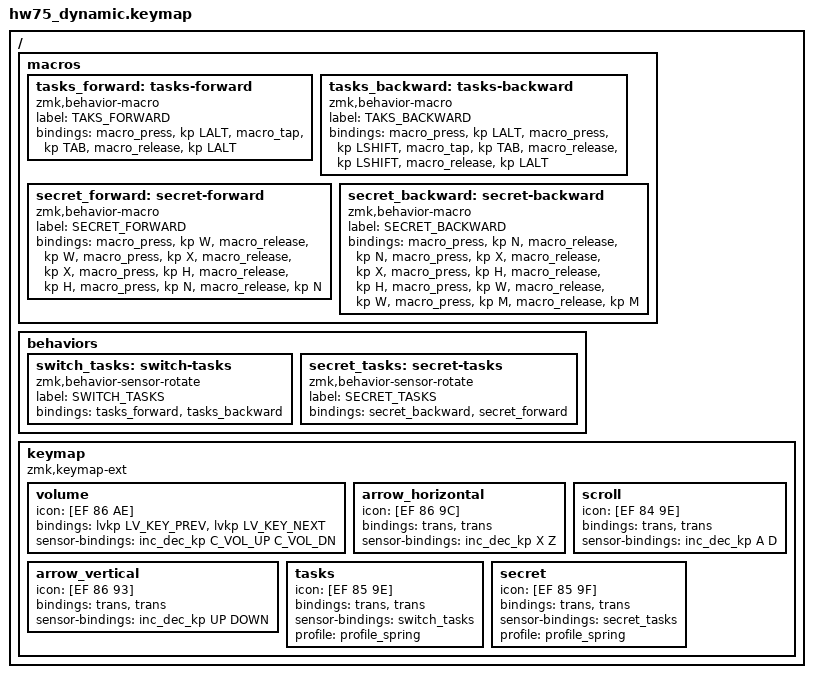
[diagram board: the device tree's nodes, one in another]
/*
 * Copyright (c) 2022 The ZMK Contributors
 * SPDX-License-Identifier: MIT
 */

#include <behaviors.dtsi>
#include <behaviors/lvgl_key_press.dtsi>
#include <behaviors/sensor_rotate_mouse_wheel.dtsi>
#include <dt-bindings/zmk/keys.h>
#include <dt-bindings/zmk/rgb.h>
#include <dt-bindings/zmk/lvgl.h>
#include <dt-bindings/zmk/mouse.h>

/ {
	macros {
		tasks_forward: tasks-forward {
			label = "TAKS_FORWARD";
			compatible = "zmk,behavior-macro";
			#binding-cells = <0>;
			bindings = <&macro_press   &kp LALT>,
				   <&macro_tap     &kp TAB>,
				   <&macro_release &kp LALT>;
		};

		tasks_backward: tasks-backward {
			label = "TAKS_BACKWARD";
			compatible = "zmk,behavior-macro";
			#binding-cells = <0>;
			bindings = <&macro_press   &kp LALT>,
				   <&macro_press   &kp LSHIFT>,
				   <&macro_tap     &kp TAB>,
				   <&macro_release &kp LSHIFT>,
				   <&macro_release &kp LALT>;
		};

		secret_forward: secret-forward {
			label = "SECRET_FORWARD";
			compatible = "zmk,behavior-macro";
			#binding-cells = <0>;
			bindings = <&macro_press   &kp W>,
				   <&macro_release   &kp W>,
				   <&macro_press   &kp X>,
				   <&macro_release   &kp X>,
				   <&macro_press     &kp H>,
				   <&macro_release   &kp H>,
				   <&macro_press &kp N>,
				   <&macro_release &kp N>;
		};

		secret_backward: secret-backward {
			label = "SECRET_BACKWARD";
			compatible = "zmk,behavior-macro";
			#binding-cells = <0>;
			bindings = <&macro_press   &kp N>,
				   <&macro_release   &kp N>,
				   <&macro_press   &kp X>,
				   <&macro_release   &kp X>,
				   <&macro_press     &kp H>,
				   <&macro_release   &kp H>,
				   <&macro_press &kp W>,
				   <&macro_release &kp W>,
				   <&macro_press &kp M>,
				   <&macro_release &kp M>;
		};
	};

	behaviors {
		switch_tasks: switch-tasks {
			compatible = "zmk,behavior-sensor-rotate";
			label = "SWITCH_TASKS";
			#sensor-binding-cells = <0>;
			bindings = <&tasks_forward>, <&tasks_backward>;
		};

		secret_tasks: secret-tasks {
			compatible = "zmk,behavior-sensor-rotate";
			label = "SECRET_TASKS";
			#sensor-binding-cells = <0>;
			bindings = <&secret_backward>, <&secret_forward>;
		};
	};

	keymap {
		compatible = "zmk,keymap-ext", "zmk,keymap";

		volume {
			label = "音量";
			icon = [EF 86 AE];
			bindings = <&lvkp LV_KEY_PREV &lvkp LV_KEY_NEXT>;
			sensor-bindings = <&inc_dec_kp C_VOL_UP C_VOL_DN>;
		};

		arrow_horizontal {
			label = "左右";
			icon = [EF 86 9C];
			bindings = <&trans &trans>;
			sensor-bindings = <&inc_dec_kp X Z>;
		};

		scroll {
			label = "倍速";
			icon = [EF 84 9E];
			bindings = <&trans &trans>;
			sensor-bindings = <&inc_dec_kp A D>;
		};

		arrow_vertical {
			label = "上下";
			icon = [EF 86 93];
			bindings = <&trans &trans>;
			sensor-bindings = <&inc_dec_kp UP DOWN>;
		};

		tasks {
			label = "窗口";
			icon = [EF 85 9E];
			bindings = <&trans &trans>;
			sensor-bindings = <&switch_tasks>;
			profile = <&profile_spring>;
		};

		secret {
			label = "秘密";
			icon = [EF 85 9F];
			bindings = <&trans &trans>;
			sensor-bindings = <&secret_tasks>;
			profile = <&profile_spring>;
		};

	};
};
